# nrf54h20_engb_sysctrl register map
Vendor: Nordic Semiconductor; Series: nRF54h; File version: 1
Registers are 32-bit, read-write, reset 0x0 unless marked. A register's access mark holds for its fields unless they carry their own. Offsets are from the block's base; [hi:lo] are bit positions; lines under a group give offsets from that group; 'fields as' and 'values as' point back to an identical list.

## MBIAS — MBIAS peripheral
Base 0x5F96D000
0x00 TASKS_PWRUPIBPP wo — Power up IBPP currents
  [0] TASKS_PWRUPIBPP
    1=Trigger task
0x04 TASKS_PWRUPIBPSR wo — Power up IBPSR currents
  [0] TASKS_PWRUPIBPSR
    1=Trigger task
0x08 TASKS_PWRDOWNIBPP wo — Power down IBPP currents
  [0] TASKS_PWRDOWNIBPP
    1=Trigger task
0x0C TASKS_PWRDOWNIBPSR wo — Power down IBPSR currents
  [0] TASKS_PWRDOWNIBPSR
    1=Trigger task
0x100 EVENTS_READYIBPP — Power up for IBPP currents is done
  [0] EVENTS_READYIBPP
    0=NotGenerated (Event not generated); 1=Generated (Event generated)
0x104 EVENTS_READYIBPSR — Power up for IBPSR currents is done
  [0] EVENTS_READYIBPSR
    values as EVENTS_READYIBPP.EVENTS_READYIBPP
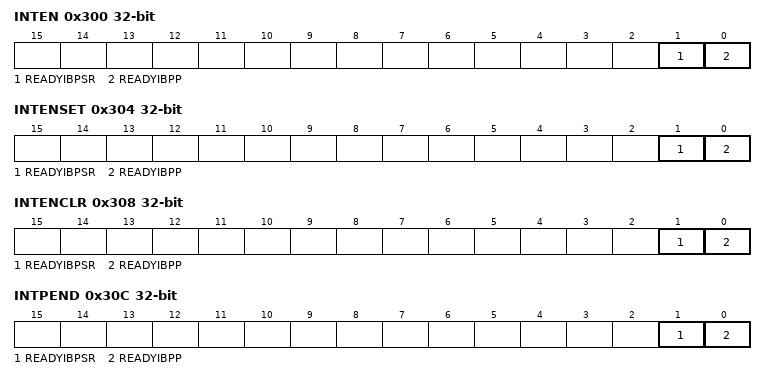
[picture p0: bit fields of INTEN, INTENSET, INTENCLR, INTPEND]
0x300 INTEN — Enable or disable interrupt
  [1] READYIBPSR — Enable or disable interrupt for event READYIBPSR
    0=Disabled; 1=Enabled
  [0] READYIBPP — Enable or disable interrupt for event READYIBPP
    0=Disabled; 1=Enabled
0x304 INTENSET — Enable interrupt
  [1] READYIBPSR — Write '1' to enable interrupt for event READYIBPSR
    on read: 0=Disabled (Read: Disabled); 1=Enabled (Read: Enabled) | on write: 1=Set (Enable)
  [0] READYIBPP — Write '1' to enable interrupt for event READYIBPP
    values as READYIBPSR
0x308 INTENCLR — Disable interrupt
  [1] READYIBPSR — Write '1' to disable interrupt for event READYIBPSR
    on read: 0=Disabled (Read: Disabled); 1=Enabled (Read: Enabled) | on write: 1=Clear (Disable)
  [0] READYIBPP — Write '1' to disable interrupt for event READYIBPP
    values as READYIBPSR
0x30C INTPEND ro — Pending interrupts
  [1] READYIBPSR — Read pending status of interrupt for event READYIBPSR
    on read: 0=NotPending (Read: Not pending); 1=Pending (Read: Pending)
  [0] READYIBPP — Read pending status of interrupt for event READYIBPP
    values as READYIBPSR
0x400 STATUS ro — MBIAS status
  [0] MODE — Current MBIAS mode
    0=Normal mode; 1=Refresh mode
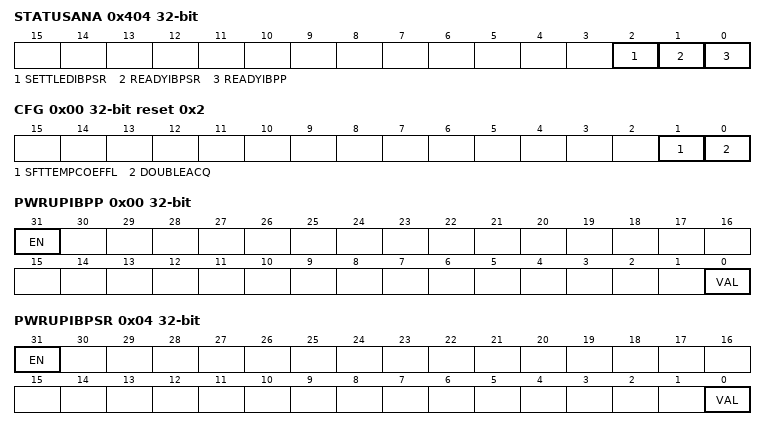
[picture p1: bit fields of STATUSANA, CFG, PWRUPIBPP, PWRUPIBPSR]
0x404 STATUSANA ro — Status of analog module output signals
  [2] SETTLEDIBPSR — Current value of the SETTLED_IBPSR signal from the analog module
  [1] READYIBPSR — Current value of the READY_IBPSR signal from the analog module
  [0] READYIBPP — Current value of the READY_IBPP signal from the analog module
0x410 CONFIG group — Unspecified
  0x00 CFG reset 0x2 — MBIAS configuration
    [1] SFTTEMPCOEFFL — Shift temperature coefficient configuration
      0=Disabled (Shift temperature coefficient 74 ppm/C lower is disabled); 1=Enabled (Shift temperature coefficient 74 ppm/C lower is enabled)
    [0] DOUBLEACQ — Double the acquisition time in refresh mode
      0=Disabled (Double the acquisition time in refresh modet is disabled); 1=Enabled (Double the acquisition time in refresh mode is enabled)
0x440 TRIM group — Unspecified
  0x00 MBIASIBPP reset 0x1 — IBPP current trimming
    [2:0] VAL — IBPP Current trimming value
      0=Normal trim value; 1=The trim value is 23 percent; 2=The trim value is 54 percent; 3=The trim value is 98 percent; 4=ValNeg51 (The trim value is -51 percent); 5=ValNeg42 (The trim value is -42 percent); 6=ValNeg31 (The trim value is -31 percent); 7=ValNeg18 (The trim value is -18 percent)
  0x04 MBIASIBPSR — IBPSR current and VREF voltage trimming
    [4:0] VAL — IBPSR current and VREF voltage trimming value
0x480 MIRROR reset 0x1 — Enable LOCK for mirrored registers
  [0] LOCK — Lock for mirrored registers
    0=Disabled (Lock disabled); 1=Enabled (Lock enabled)
0x484 MODE — MBIAS mode
  [1:0] MODE
    0=Automatically handled by the peripheral; 1=Normal mode - IBPSR current are continuous ON; 2=Refresh mode - IBPSR currents are duty cycled
0x500 OVERRIDE group — Unspecified
  0x00 PWRUPIBPP — Override the PWRUP_IBPP signal to the analog module
    [31] EN — Enable the override
      0=Disabled (Override is disabled); 1=Enabled (Override is enabled)
    [0] VAL — Override value for the signal
  0x04 PWRUPIBPSR — Override the PWRUP_IBPSR signal to the analog module
    fields as OVERRIDE.PWRUPIBPP
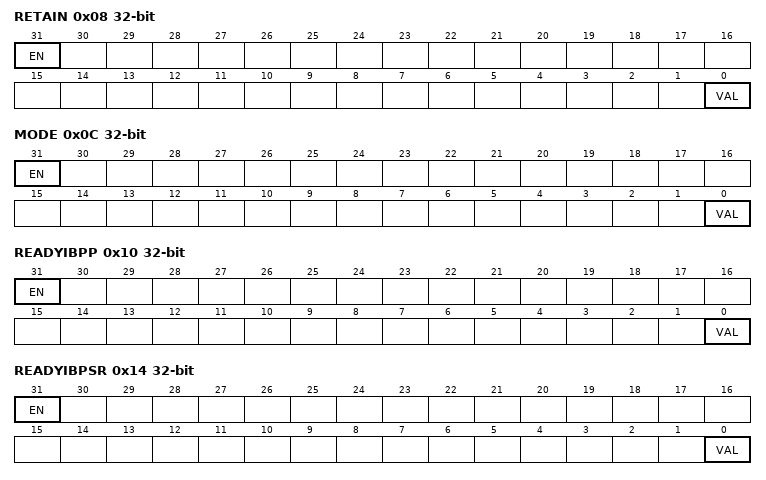
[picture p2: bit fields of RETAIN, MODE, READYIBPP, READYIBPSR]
  0x08 RETAIN — Override the RETAIN signal to the analog module
    fields as OVERRIDE.PWRUPIBPP
  0x0C MODE — Override the MODE signal to the analog module
    fields as OVERRIDE.PWRUPIBPP
  0x10 READYIBPP — Override the READY_IBPP signal from the analog module
    [31] EN — Enable the override
      values as OVERRIDE.PWRUPIBPP.EN
    [0] VAL — Current value of the signal
  0x14 READYIBPSR — Override the READY_IBPSR signal from the analog module
    fields as OVERRIDE.READYIBPP
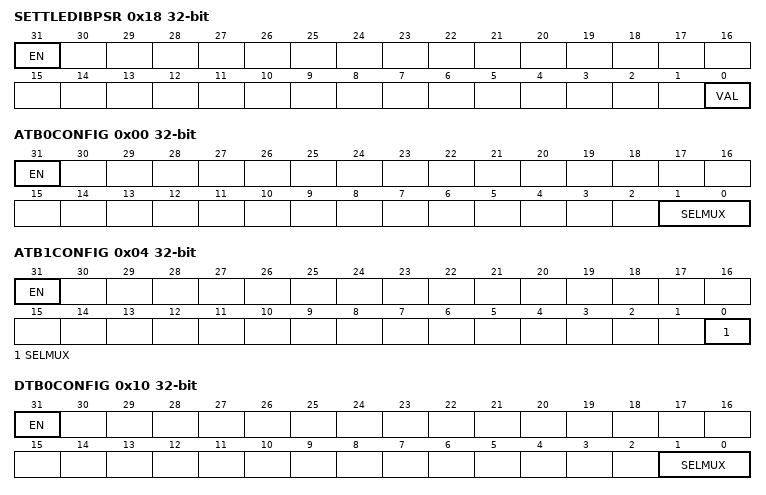
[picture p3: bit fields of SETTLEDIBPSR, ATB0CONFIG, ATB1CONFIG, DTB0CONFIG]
  0x18 SETTLEDIBPSR — Override the SETTLED_IBPSR signal from the analog module
    fields as OVERRIDE.READYIBPP
0x600 DFT group — Unspecified
  0x00 ATB0CONFIG — Analog Test Bus 0 (ATB0) configuration
    [31] EN — Enable the analog test bus
      0=Disabled (Analog test bus is disabled); 1=Enabled (Analog test bus is enabled)
    [1:0] SELMUX — Select multiplexer for ATB0
      0=None selected; 1=ConnectAVSS; 2=Connect8uAIBPSRcurrent; 3=Connect50nAIBPPcurrent
  0x04 ATB1CONFIG — Analog Test Bus 1 (ATB1) configuration
    [31] EN — Enable the analog test bus
      values as DFT.ATB0CONFIG.EN
    [0] SELMUX — Select multiplexer for ATB1
      0=ConnectbufVREF0V9RFR (Connect buffered VREF_0V9_RFR); 1=ConnectbufVREF0V9 (Connect buffered VREF_0V9)
  0x10 DTB0CONFIG — Digital Test Bus 0 (DTB0) configuration
    [31] EN — Enable the digital test bus
      0=Disabled (Digital test bus is disabled); 1=Enabled (Digital test bus is enabled)
    [1:0] SELMUX — Select multiplexer for DTB0
      0=READYIBPP (READYIBPP selected); 1=READYIBPSR (READYIBPSR selected); 2=SETTLEDIBPSRDIG (SETTLEDIBPSRDIG selected); 3=SETTLEDIBPSRANA (SETTLEDIBPSRANA selected)
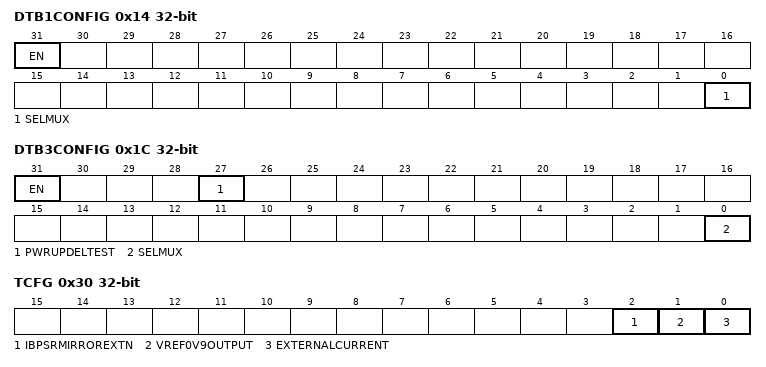
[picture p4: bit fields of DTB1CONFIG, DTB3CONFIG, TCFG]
  0x14 DTB1CONFIG — Digital Test Bus 1 (DTB1) configuration
    [31] EN — Enable the digital test bus
      values as DFT.DTB0CONFIG.EN
    [0] SELMUX — Select multiplexer for DTB1
      0=OSCRFRANA (OSCRFRANA selected); 1=SETTLEDIBPSR (SETTLEDIBPSR selected)
  0x1C DTB3CONFIG — Digital Test Bus 3 (DTB3) configuration
    [31] EN — Enable the digital test bus
      values as DFT.DTB0CONFIG.EN
    [27] PWRUPDELTEST — Enable the PWRUP delay test circuit
      0=Disabled (PWRUP delay test circuit is disabled); 1=Enabled (PWRUP delay test circuit is enabled)
    [0] SELMUX — Select multiplexer for DTB3
      0=PWRUPIBPP (PWRUPIBPP selected); 1=PWRUPIBPSR (PWRUPIBPSR selected)
  0x30 TCFG — Test mode configuration
    [2] IBPSRMIRROREXTN — Disable IBPSR mirror extension
      0=Enabled (IBPSR mirror extension is enabled); 1=Disabled (IBPSR mirror extension is disabled)
    [1] VREF0V9OUTPUT — Enable VREF_0V9 output
      0=Disabled (VREF_0V9 output is disabled); 1=Enabled (VREF_0V9 output is enabled)
    [0] EXTERNALCURRENT — Use 8uA external current on ATB0_1V8 as reference for IBPSR
      0=Disabled (External current is disabled); 1=Enabled (External current is enabled)
